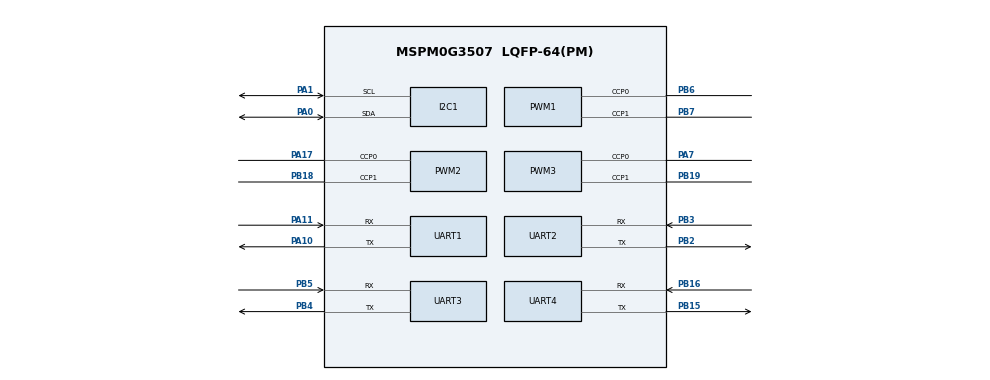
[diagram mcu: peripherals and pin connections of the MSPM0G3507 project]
/**
 * These arguments were used when this file was generated. They will be automatically applied on subsequent loads
 * via the GUI or CLI. Run CLI with '--help' for additional information on how to override these arguments.
 * @cliArgs --device "MSPM0G350X" --part "Default" --package "LQFP-64(PM)" --product "mspm0_sdk@2.02.00.05"
 * @v2CliArgs --device "MSPM0G3507" --package "LQFP-64(PM)" --product "mspm0_sdk@2.02.00.05"
 * @versions {"tool":"1.21.1+3772"}
 */

/**
 * Import the modules used in this configuration.
 */
const I2C     = scripting.addModule("/ti/driverlib/I2C", {}, false);
const I2C1    = I2C.addInstance();
const PWM     = scripting.addModule("/ti/driverlib/PWM", {}, false);
const PWM1    = PWM.addInstance();
const PWM2    = PWM.addInstance();
const PWM3    = PWM.addInstance();
const SYSCTL  = scripting.addModule("/ti/driverlib/SYSCTL");
const SYSTICK = scripting.addModule("/ti/driverlib/SYSTICK");
const TIMER   = scripting.addModule("/ti/driverlib/TIMER", {}, false);
const TIMER1  = TIMER.addInstance();
const UART    = scripting.addModule("/ti/driverlib/UART", {}, false);
const UART1   = UART.addInstance();
const UART2   = UART.addInstance();
const UART3   = UART.addInstance();
const UART4   = UART.addInstance();

/**
 * Write custom configuration values to the imported modules.
 */
const divider6       = system.clockTree["PLL_CLK2X_DIV"];
divider6.divideValue = 4;

const divider7       = system.clockTree["PLL_PDIV"];
divider7.divideValue = 2;

const divider9       = system.clockTree["UDIV"];
divider9.divideValue = 2;

const gate7  = system.clockTree["MFCLKGATE"];
gate7.enable = true;

const multiplier2         = system.clockTree["PLL_QDIV"];
multiplier2.multiplyValue = 10;

const mux8       = system.clockTree["HSCLKMUX"];
mux8.inputSelect = "HSCLKMUX_SYSPLL2X";

I2C1.$name                             = "I2C_VL53L0X";
I2C1.peripheral.$assign                = "I2C0";
I2C1.peripheral.sdaPin.$assign         = "PA0";
I2C1.peripheral.sclPin.$assign         = "PA1";
I2C1.sdaPinConfig.hideOutputInversion  = scripting.forceWrite(false);
I2C1.sdaPinConfig.onlyInternalResistor = scripting.forceWrite(false);
I2C1.sdaPinConfig.passedPeripheralType = scripting.forceWrite("Digital");
I2C1.sdaPinConfig.$name                = "ti_driverlib_gpio_GPIOPinGeneric8";
I2C1.sclPinConfig.hideOutputInversion  = scripting.forceWrite(false);
I2C1.sclPinConfig.onlyInternalResistor = scripting.forceWrite(false);
I2C1.sclPinConfig.passedPeripheralType = scripting.forceWrite("Digital");
I2C1.sclPinConfig.$name                = "ti_driverlib_gpio_GPIOPinGeneric9";

const Board = scripting.addModule("/ti/driverlib/Board", {}, false);

PWM1.$name                      = "PWM_0";
PWM1.pwmMode                    = "EDGE_ALIGN_UP";
PWM1.clockPrescale              = 160;
PWM1.timerCount                 = 10000;
PWM1.peripheral.$assign         = "TIMG6";
PWM1.peripheral.ccp0Pin.$assign = "PB6";
PWM1.peripheral.ccp1Pin.$assign = "PB7";
PWM1.PWM_CHANNEL_0.$name        = "ti_driverlib_pwm_PWMTimerCC0";
PWM1.PWM_CHANNEL_0.dutyCycle    = 50;
PWM1.PWM_CHANNEL_1.$name        = "ti_driverlib_pwm_PWMTimerCC1";
PWM1.ccp0PinConfig.$name        = "ti_driverlib_gpio_GPIOPinGeneric10";
PWM1.ccp1PinConfig.$name        = "ti_driverlib_gpio_GPIOPinGeneric11";

PWM2.$name                      = "PWM_1";
PWM2.peripheral.$assign         = "TIMA1";
PWM2.peripheral.ccp0Pin.$assign = "PA17";
PWM2.peripheral.ccp1Pin.$assign = "PB18";
PWM2.PWM_CHANNEL_0.$name        = "ti_driverlib_pwm_PWMTimerCC2";
PWM2.PWM_CHANNEL_1.$name        = "ti_driverlib_pwm_PWMTimerCC3";
PWM2.ccp0PinConfig.$name        = "ti_driverlib_gpio_GPIOPinGeneric12";
PWM2.ccp1PinConfig.$name        = "ti_driverlib_gpio_GPIOPinGeneric13";

PWM3.$name                      = "PWM_2";
PWM3.peripheral.$assign         = "TIMG8";
PWM3.peripheral.ccp0Pin.$assign = "PA7";
PWM3.peripheral.ccp1Pin.$assign = "PB19";
PWM3.PWM_CHANNEL_0.$name        = "ti_driverlib_pwm_PWMTimerCC4";
PWM3.PWM_CHANNEL_1.$name        = "ti_driverlib_pwm_PWMTimerCC5";
PWM3.ccp0PinConfig.$name        = "ti_driverlib_gpio_GPIOPinGeneric14";
PWM3.ccp1PinConfig.$name        = "ti_driverlib_gpio_GPIOPinGeneric15";

SYSCTL.forceDefaultClkConfig = true;
SYSCTL.clockTreeEn           = true;

SYSTICK.periodEnable      = true;
SYSTICK.interruptEnable   = true;
SYSTICK.systickEnable     = true;
SYSTICK.period            = 80000;
SYSTICK.interruptPriority = "3";

TIMER1.$name              = "TIMER_0";
TIMER1.timerClkSrc        = "MFCLK";
TIMER1.interruptPriority  = "2";
TIMER1.timerMode          = "PERIODIC_UP";
TIMER1.timerPeriod        = "1ms";
TIMER1.interrupts         = ["LOAD","ZERO"];
TIMER1.peripheral.$assign = "TIMA0";

UART1.$name                            = "user";
UART1.uartClkSrc                       = "MFCLK";
UART1.targetBaudRate                   = 115200;
UART1.peripheral.rxPin.$assign         = "PA11";
UART1.peripheral.txPin.$assign         = "PA10";
UART1.txPinConfig.direction            = scripting.forceWrite("OUTPUT");
UART1.txPinConfig.hideOutputInversion  = scripting.forceWrite(false);
UART1.txPinConfig.onlyInternalResistor = scripting.forceWrite(false);
UART1.txPinConfig.passedPeripheralType = scripting.forceWrite("Digital");
UART1.txPinConfig.$name                = "ti_driverlib_gpio_GPIOPinGeneric0";
UART1.rxPinConfig.hideOutputInversion  = scripting.forceWrite(false);
UART1.rxPinConfig.onlyInternalResistor = scripting.forceWrite(false);
UART1.rxPinConfig.passedPeripheralType = scripting.forceWrite("Digital");
UART1.rxPinConfig.$name                = "ti_driverlib_gpio_GPIOPinGeneric1";

UART2.$name                            = "MSPMotor";
UART2.targetBaudRate                   = 115200;
UART2.uartClkSrc                       = "MFCLK";
UART2.enabledInterrupts                = ["RX"];
UART2.interruptPriority                = "0";
UART2.peripheral.$assign               = "UART3";
UART2.peripheral.rxPin.$assign         = "PB3";
UART2.peripheral.txPin.$assign         = "PB2";
UART2.txPinConfig.direction            = scripting.forceWrite("OUTPUT");
UART2.txPinConfig.hideOutputInversion  = scripting.forceWrite(false);
UART2.txPinConfig.onlyInternalResistor = scripting.forceWrite(false);
UART2.txPinConfig.passedPeripheralType = scripting.forceWrite("Digital");
UART2.txPinConfig.$name                = "ti_driverlib_gpio_GPIOPinGeneric2";
UART2.rxPinConfig.hideOutputInversion  = scripting.forceWrite(false);
UART2.rxPinConfig.onlyInternalResistor = scripting.forceWrite(false);
UART2.rxPinConfig.passedPeripheralType = scripting.forceWrite("Digital");
UART2.rxPinConfig.$name                = "ti_driverlib_gpio_GPIOPinGeneric3";

UART3.$name                            = "IMU";
UART3.targetBaudRate                   = 115200;
UART3.enabledInterrupts                = ["RX"];
UART3.interruptPriority                = "1";
UART3.peripheral.rxPin.$assign         = "PB5";
UART3.peripheral.txPin.$assign         = "PB4";
UART3.txPinConfig.direction            = scripting.forceWrite("OUTPUT");
UART3.txPinConfig.hideOutputInversion  = scripting.forceWrite(false);
UART3.txPinConfig.onlyInternalResistor = scripting.forceWrite(false);
UART3.txPinConfig.passedPeripheralType = scripting.forceWrite("Digital");
UART3.txPinConfig.$name                = "ti_driverlib_gpio_GPIOPinGeneric4";
UART3.rxPinConfig.hideOutputInversion  = scripting.forceWrite(false);
UART3.rxPinConfig.onlyInternalResistor = scripting.forceWrite(false);
UART3.rxPinConfig.passedPeripheralType = scripting.forceWrite("Digital");
UART3.rxPinConfig.$name                = "ti_driverlib_gpio_GPIOPinGeneric5";

UART4.$name                            = "Vision";
UART4.targetBaudRate                   = 115200;
UART4.peripheral.rxPin.$assign         = "PB16";
UART4.peripheral.txPin.$assign         = "PB15";
UART4.txPinConfig.direction            = scripting.forceWrite("OUTPUT");
UART4.txPinConfig.hideOutputInversion  = scripting.forceWrite(false);
UART4.txPinConfig.onlyInternalResistor = scripting.forceWrite(false);
UART4.txPinConfig.passedPeripheralType = scripting.forceWrite("Digital");
UART4.txPinConfig.$name                = "ti_driverlib_gpio_GPIOPinGeneric6";
UART4.rxPinConfig.hideOutputInversion  = scripting.forceWrite(false);
UART4.rxPinConfig.onlyInternalResistor = scripting.forceWrite(false);
UART4.rxPinConfig.passedPeripheralType = scripting.forceWrite("Digital");
UART4.rxPinConfig.$name                = "ti_driverlib_gpio_GPIOPinGeneric7";

/**
 * Pinmux solution for unlocked pins/peripherals. This ensures that minor changes to the automatic solver in a future
 * version of the tool will not impact the pinmux you originally saw.  These lines can be completely deleted in order to
 * re-solve from scratch.
 */
Board.peripheral.$suggestSolution          = "DEBUGSS";
Board.peripheral.swclkPin.$suggestSolution = "PA20";
Board.peripheral.swdioPin.$suggestSolution = "PA19";
UART1.peripheral.$suggestSolution          = "UART0";
UART3.peripheral.$suggestSolution          = "UART1";
UART4.peripheral.$suggestSolution          = "UART2";
